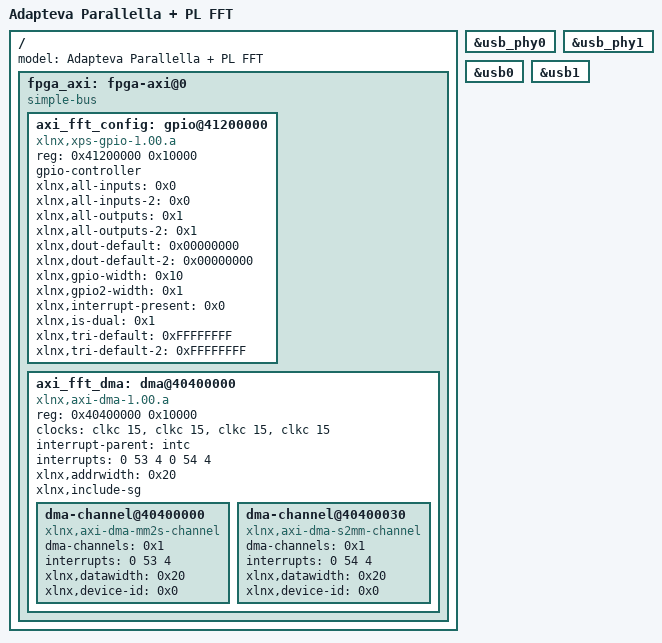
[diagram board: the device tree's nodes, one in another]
/*
 * Copyright (c) 2018 Christopher Hewitt
 *
 * This software is licensed under the terms of the GNU General Public
 * License version 2, as published by the Free Software Foundation, and
 * may be copied, distributed, and modified under those terms.
 *
 * This program is distributed in the hope that it will be useful,
 * but WITHOUT ANY WARRANTY; without even the implied warranty of
 * MERCHANTABILITY or FITNESS FOR A PARTICULAR PURPOSE.  See the
 * GNU General Public License for more details.
 */
/dts-v1/;
#include "zynq-parallella1.dtsi"

/ {
	model = "Adapteva Parallella + PL FFT";

	fpga_axi: fpga-axi@0 {
		compatible = "simple-bus";
		#address-cells = <0x1>;
		#size-cells = <0x1>;
		ranges ;

		axi_fft_config: gpio@41200000 {
			compatible = "xlnx,xps-gpio-1.00.a";
			reg = <0x41200000 0x10000>;
			gpio-controller ;
			#gpio-cells = <2>;

			xlnx,all-inputs = <0x0>;
			xlnx,all-inputs-2 = <0x0>;
			xlnx,all-outputs = <0x1>;
			xlnx,all-outputs-2 = <0x1>;
			xlnx,dout-default = <0x00000000>;
			xlnx,dout-default-2 = <0x00000000>;
			xlnx,gpio-width = <0x10>;
			xlnx,gpio2-width = <0x1>;
			xlnx,interrupt-present = <0x0>;
			xlnx,is-dual = <0x1>;
			xlnx,tri-default = <0xFFFFFFFF>;
			xlnx,tri-default-2 = <0xFFFFFFFF>;
		};

		axi_fft_dma: dma@40400000 {
			compatible = "xlnx,axi-dma-1.00.a";
			reg = <0x40400000 0x10000>;
			#dma-cells = <1>;

			clock-names = "s_axi_lite_aclk", "m_axi_sg_aclk", "m_axi_mm2s_aclk", "m_axi_s2mm_aclk";
			clocks = <&clkc 15>, <&clkc 15>, <&clkc 15>, <&clkc 15>;

			interrupt-parent = <&intc>;
			interrupts = <0 53 4 0 54 4>;

			xlnx,addrwidth = <0x20>;
			xlnx,include-sg ;

			dma-channel@40400000 {
				compatible = "xlnx,axi-dma-mm2s-channel";
				dma-channels = <0x1>;
				interrupts = <0 53 4>;
				xlnx,datawidth = <0x20>;
				xlnx,device-id = <0x0>;
			};
			dma-channel@40400030 {
				compatible = "xlnx,axi-dma-s2mm-channel";
				dma-channels = <0x1>;
				interrupts = <0 54 4>;
				xlnx,datawidth = <0x20>;
				xlnx,device-id = <0x0>;
			};
		};
	};
};

&usb_phy0 {
	status = "okay";
};

&usb_phy1 {
	status = "okay";
};

&usb0 {
	status = "okay";
};

&usb1 {
	status = "okay";
};

